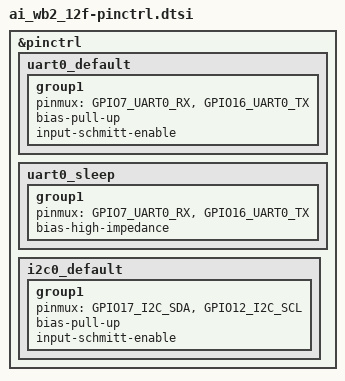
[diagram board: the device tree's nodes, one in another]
/*
 * Copyright (c) 2024-2025 MASSDRIVER EI (massdriver.space)
 *
 * SPDX-License-Identifier: Apache-2.0
 */

#include <dt-bindings/pinctrl/bl602x-pinctrl.h>

&pinctrl {
	uart0_default: uart0_default {
		group1 {
			pinmux = <GPIO7_UART0_RX>,
				 <GPIO16_UART0_TX>;
			bias-pull-up;
			input-schmitt-enable;
		};
	};

	uart0_sleep: uart0_sleep {
		group1 {
			pinmux = <GPIO7_UART0_RX>,
				 <GPIO16_UART0_TX>;
			bias-high-impedance;
		};
	};

	i2c0_default: i2c0_default {
		group1 {
			pinmux = <GPIO17_I2C_SDA>,
				 <GPIO12_I2C_SCL>;
			bias-pull-up;
			input-schmitt-enable;
		};
	};
};
